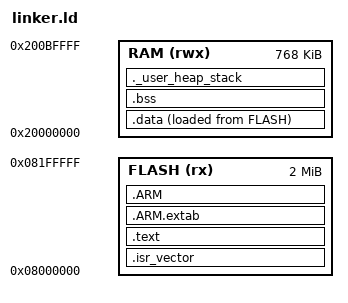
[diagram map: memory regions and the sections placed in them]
/*
 * linker.ld — Linker script for STM32U575ZIT6
 *
 * Author: jayis1
 * Copyright (C) 2026 jayis1. All rights reserved.
 * License: GPL-3.0
 */

/* STM32U575ZIT6 has 2 MB Flash and 768 KB SRAM. */
ENTRY(Reset_Handler)

_estack = ORIGIN(RAM) + LENGTH(RAM);

MEMORY
{
    FLASH (rx)  : ORIGIN = 0x08000000, LENGTH = 2048K
    RAM   (rwx) : ORIGIN = 0x20000000, LENGTH = 768K
}

SECTIONS
{
    /* Interrupt vector table at the start of flash */
    .isr_vector :
    {
        . = ALIGN(4);
        KEEP(*(.isr_vector))
        . = ALIGN(4);
    } > FLASH

    /* Code and read-only data */
    .text :
    {
        . = ALIGN(4);
        *(.text)
        *(.text*)
        *(.rodata)
        *(.rodata*)
        . = ALIGN(4);
        _etext = .;
    } > FLASH

    /* ARM extended unwinding tables */
    .ARM.extab :
    {
        *(.ARM.extab* .gnu.linkonce.armextab.*)
    } > FLASH

    .ARM :
    {
        __exidx_start = .;
        *(.ARM.exidx*)
        __exidx_end = .;
    } > FLASH

    /* Load addresses for .data initialization */
    _sidata = LOADADDR(.data);

    /* Initialized data (copied from flash to RAM at startup) */
    .data :
    {
        . = ALIGN(4);
        _sdata = .;
        *(.data)
        *(.data*)
        . = ALIGN(4);
        _edata = .;
    } > RAM AT > FLASH

    /* Zero-initialized data */
    .bss :
    {
        . = ALIGN(4);
        _sbss = .;
        *(.bss)
        *(.bss*)
        *(COMMON)
        . = ALIGN(4);
        _ebss = .;
    } > RAM

    /* Heap and stack (stack grows down from _estack) */
    ._user_heap_stack :
    {
        . = ALIGN(8);
        PROVIDE(end = .);
        PROVIDE(_end = .);
        . = . + 0x400;   /* 1 KB minimum heap */
        . = ALIGN(8);
    } > RAM

    /* Discard sections we don't need */
    /DISCARD/ :
    {
        *(.ARM.attributes)
        *(.comment)
    }
}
